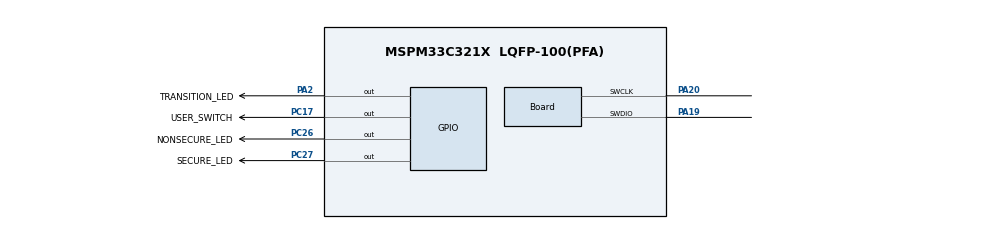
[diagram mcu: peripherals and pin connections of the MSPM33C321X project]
/**
 * @cliArgs --device "MSPM33C321X" --part "Default" --package "LQFP-100(PFA)" --product "mspm33_sdk@1.02.00.00"
 * @versions {"tool":"1.26.0+4407"}
 */
// @cliArgs --board /ti/boards/LP_MSPM33C321A --rtos nortos

/**
 * Import the modules used in this configuration.
 */
const GPIO   = scripting.addModule("/ti/driverlib/GPIO", {}, false);
const GPIO1  = GPIO.addInstance();
const GPIO2  = GPIO.addInstance();
const GSC    = scripting.addModule("/ti/driverlib/GSC", {}, false);
const GSC1   = GSC.addInstance();
const SYSCTL = scripting.addModule("/ti/driverlib/SYSCTL");

/**
 * Write custom configuration values to the imported modules.
 */
GPIO1.$name                               = "LED_GRP";
GPIO1.associatedPins.create(3);
GPIO1.associatedPins[0].$name             = "SECURE_LED";
GPIO1.associatedPins[0].launchPadShortcut = "LED2GreenEn";
GPIO1.associatedPins[0].pin.$assign       = "PC27";
GPIO1.associatedPins[1].$name             = "NONSECURE_LED";
GPIO1.associatedPins[1].launchPadShortcut = "LED2RedEn";
GPIO1.associatedPins[1].pin.$assign       = "PC26";
GPIO1.associatedPins[2].$name             = "TRANSITION_LED";
GPIO1.associatedPins[2].launchPadShortcut = "LED2BlueEn";
GPIO1.associatedPins[2].pin.$assign       = "PA2";

const Board                       = scripting.addModule("/ti/driverlib/Board", {}, false);
Board.peripheral.$assign          = "DEBUGSS";
Board.peripheral.swclkPin.$assign = "PA20";
Board.peripheral.swdioPin.$assign = "PA19";

GPIO2.$name                               = "BUTTON_GRP";
GPIO2.associatedPins[0].$name             = "USER_SWITCH";
GPIO2.associatedPins[0].interruptEn       = true;
GPIO2.associatedPins[0].launchPadShortcut = "Button2En";
GPIO2.associatedPins[0].polarity          = "FALL";
GPIO2.associatedPins[0].pin.$assign       = "PC17";

GSC1.$name                = "CONFIG_GSC_0";
GSC1.secure_sram_size     = 64;
GSC1.privileged_sram_size = 256;
GSC1.secure_sysctl        = false;
GSC1.privileged_sysctl    = false;
GSC1.secure_gpioa         = true;

SYSCTL.forceDefaultClkConfig = true;
SYSCTL.peripheral.$assign    = "SYSCTL";

const ProjectConfig              = scripting.addModule("/ti/project_config/ProjectConfig", {}, false);
ProjectConfig.migrationCondition = true;
ProjectConfig.genLinker          = false;
ProjectConfig.genStartup         = false;
ProjectConfig.genOpts            = false;
ProjectConfig.genLibs            = false;
